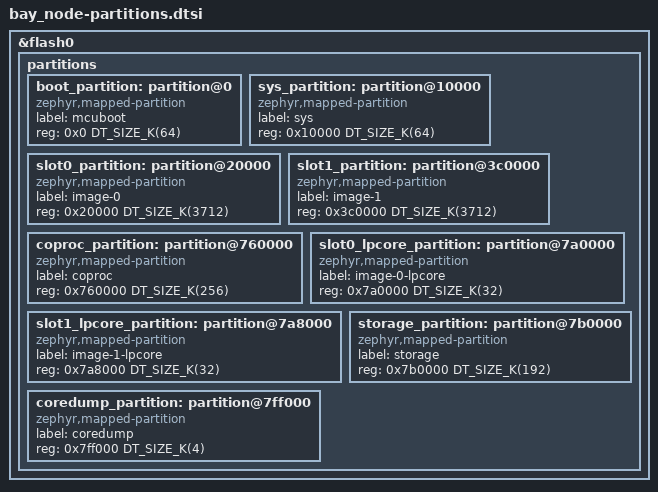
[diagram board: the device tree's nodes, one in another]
/*
 * The bay node's 8 MB of flash: Zephyr's espressif/partitions_0x0_default_8M.dtsi
 * with each image slot 128 KB smaller (3712 KB, the image is about 1.1 MB),
 * which leaves 256 KB for the DATA x4 co-processor's image (`coproc`, the
 * analyzer loaded into its SRAM at each power-up: docs/firmware.md).  The
 * partitions after it keep their places.
 *
 * SPDX-License-Identifier: Apache-2.0
 */

&flash0 {
	partitions {
		ranges;
		#address-cells = <1>;
		#size-cells = <1>;

		boot_partition: partition@0 {
			compatible = "zephyr,mapped-partition";
			label = "mcuboot";
			reg = <0x0 DT_SIZE_K(64)>;
		};

		sys_partition: partition@10000 {
			compatible = "zephyr,mapped-partition";
			label = "sys";
			reg = <0x10000 DT_SIZE_K(64)>;
		};

		slot0_partition: partition@20000 {
			compatible = "zephyr,mapped-partition";
			label = "image-0";
			reg = <0x20000 DT_SIZE_K(3712)>;
		};

		slot1_partition: partition@3c0000 {
			compatible = "zephyr,mapped-partition";
			label = "image-1";
			reg = <0x3c0000 DT_SIZE_K(3712)>;
		};

		coproc_partition: partition@760000 {
			compatible = "zephyr,mapped-partition";
			label = "coproc";
			reg = <0x760000 DT_SIZE_K(256)>;
		};

		slot0_lpcore_partition: partition@7a0000 {
			compatible = "zephyr,mapped-partition";
			label = "image-0-lpcore";
			reg = <0x7a0000 DT_SIZE_K(32)>;
		};

		slot1_lpcore_partition: partition@7a8000 {
			compatible = "zephyr,mapped-partition";
			label = "image-1-lpcore";
			reg = <0x7a8000 DT_SIZE_K(32)>;
		};

		storage_partition: partition@7b0000 {
			compatible = "zephyr,mapped-partition";
			label = "storage";
			reg = <0x7b0000 DT_SIZE_K(192)>;
		};

		coredump_partition: partition@7ff000 {
			compatible = "zephyr,mapped-partition";
			label = "coredump";
			reg = <0x7ff000 DT_SIZE_K(4)>;
		};
	};
};
